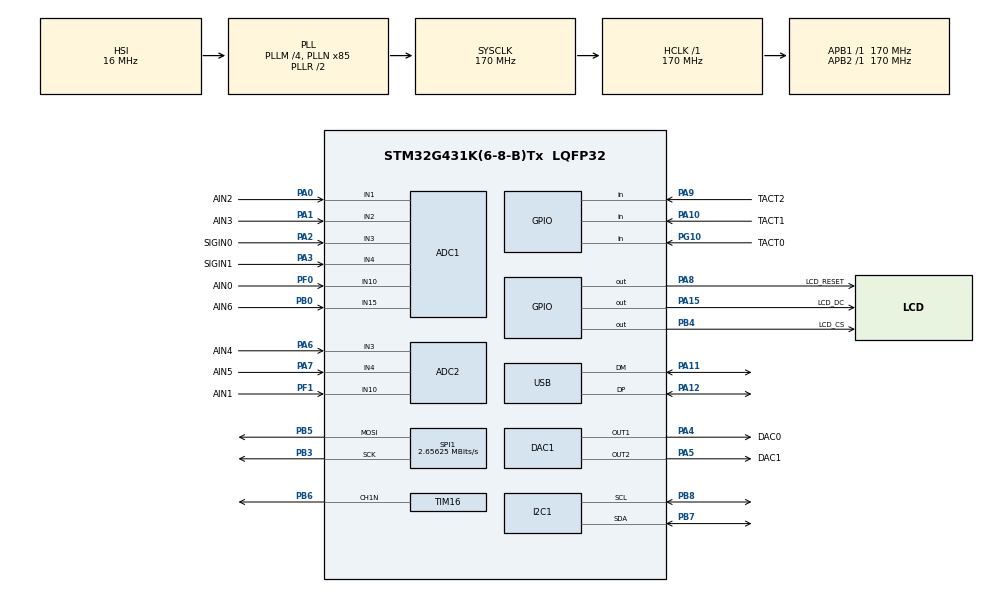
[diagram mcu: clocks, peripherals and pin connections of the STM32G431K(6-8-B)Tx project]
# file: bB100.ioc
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ADC1.Channel-0\#ChannelRegularConversion=ADC_CHANNEL_1
ADC1.Channel-1\#ChannelRegularConversion=ADC_CHANNEL_3
ADC1.Channel-2\#ChannelRegularConversion=ADC_CHANNEL_10
ADC1.Channel-3\#ChannelRegularConversion=ADC_CHANNEL_15
ADC1.EOCSelection=ADC_EOC_SEQ_CONV
ADC1.ExternalTrigConv=ADC_EXTERNALTRIG_T6_TRGO
ADC1.NbrOfConversion=4
ADC1.NbrOfConversionFlag=1
ADC1.OffsetNumber-0\#ChannelRegularConversion=ADC_OFFSET_NONE
ADC1.OffsetNumber-1\#ChannelRegularConversion=ADC_OFFSET_NONE
ADC1.OffsetNumber-2\#ChannelRegularConversion=ADC_OFFSET_NONE
ADC1.OffsetNumber-3\#ChannelRegularConversion=ADC_OFFSET_NONE
ADC1.Rank-0\#ChannelRegularConversion=1
ADC1.Rank-1\#ChannelRegularConversion=2
ADC1.Rank-2\#ChannelRegularConversion=3
ADC1.Rank-3\#ChannelRegularConversion=4
ADC1.SamplingTime-0\#ChannelRegularConversion=ADC_SAMPLETIME_2CYCLES_5
ADC1.SamplingTime-1\#ChannelRegularConversion=ADC_SAMPLETIME_2CYCLES_5
ADC1.SamplingTime-2\#ChannelRegularConversion=ADC_SAMPLETIME_2CYCLES_5
ADC1.SamplingTime-3\#ChannelRegularConversion=ADC_SAMPLETIME_2CYCLES_5
ADC1.SingleDiff-0\#ChannelRegularConversion=ADC_DIFFERENTIAL_ENDED
ADC1.SingleDiff-1\#ChannelRegularConversion=ADC_DIFFERENTIAL_ENDED
ADC1.master=1
ADC2.Channel-0\#ChannelRegularConversion=ADC_CHANNEL_3
ADC2.Channel-1\#ChannelRegularConversion=ADC_CHANNEL_4
ADC2.Channel-2\#ChannelRegularConversion=ADC_CHANNEL_10
ADC2.ExternalTrigConv=ADC_EXTERNALTRIG_T7_TRGO
ADC2.NbrOfConversion=3
ADC2.NbrOfConversionFlag=1
ADC2.OffsetNumber-0\#ChannelRegularConversion=ADC_OFFSET_NONE
ADC2.OffsetNumber-1\#ChannelRegularConversion=ADC_OFFSET_NONE
ADC2.OffsetNumber-2\#ChannelRegularConversion=ADC_OFFSET_NONE
ADC2.Rank-0\#ChannelRegularConversion=1
ADC2.Rank-1\#ChannelRegularConversion=2
ADC2.Rank-2\#ChannelRegularConversion=3
ADC2.SamplingTime-0\#ChannelRegularConversion=ADC_SAMPLETIME_2CYCLES_5
ADC2.SamplingTime-1\#ChannelRegularConversion=ADC_SAMPLETIME_2CYCLES_5
ADC2.SamplingTime-2\#ChannelRegularConversion=ADC_SAMPLETIME_2CYCLES_5
DAC1.DAC_Channel-DAC_OUT2_ExtAndInt=DAC_CHANNEL_2
DAC1.DAC_DMADoubleDataMode-DAC_OUT1_ExtAndInt=DISABLE
DAC1.DAC_SampleAndHold-DAC_OUT1_ExtAndInt=DAC_SAMPLEANDHOLD_DISABLE
DAC1.DAC_Trigger_OUT1-DAC_OUT1_ExtAndInt=DAC_TRIGGER_T6_TRGO
DAC1.DAC_Trigger_OUT2-DAC_OUT2_ExtAndInt=DAC_TRIGGER_T7_TRGO
Dma.ADC1.2.Direction=DMA_PERIPH_TO_MEMORY
Dma.ADC1.2.EventEnable=DISABLE
Dma.ADC1.2.Instance=DMA1_Channel3
Dma.ADC1.2.MemDataAlignment=DMA_MDATAALIGN_HALFWORD
Dma.ADC1.2.MemInc=DMA_MINC_ENABLE
Dma.ADC1.2.Mode=DMA_CIRCULAR
Dma.ADC1.2.PeriphDataAlignment=DMA_PDATAALIGN_HALFWORD
Dma.ADC1.2.PeriphInc=DMA_PINC_DISABLE
Dma.ADC1.2.Polarity=HAL_DMAMUX_REQ_GEN_RISING
Dma.ADC1.2.Priority=DMA_PRIORITY_LOW
Dma.ADC1.2.RequestNumber=1
Dma.ADC1.2.SignalID=NONE
Dma.ADC1.2.SyncEnable=DISABLE
Dma.ADC1.2.SyncPolarity=HAL_DMAMUX_SYNC_NO_EVENT
Dma.ADC1.2.SyncRequestNumber=1
Dma.ADC1.2.SyncSignalID=NONE
Dma.ADC2.3.Direction=DMA_PERIPH_TO_MEMORY
Dma.ADC2.3.EventEnable=DISABLE
Dma.ADC2.3.Instance=DMA1_Channel4
Dma.ADC2.3.MemDataAlignment=DMA_MDATAALIGN_HALFWORD
Dma.ADC2.3.MemInc=DMA_MINC_ENABLE
Dma.ADC2.3.Mode=DMA_CIRCULAR
Dma.ADC2.3.PeriphDataAlignment=DMA_PDATAALIGN_HALFWORD
Dma.ADC2.3.PeriphInc=DMA_PINC_DISABLE
Dma.ADC2.3.Polarity=HAL_DMAMUX_REQ_GEN_RISING
Dma.ADC2.3.Priority=DMA_PRIORITY_LOW
Dma.ADC2.3.RequestNumber=1
Dma.ADC2.3.SignalID=NONE
Dma.ADC2.3.SyncEnable=DISABLE
Dma.ADC2.3.SyncPolarity=HAL_DMAMUX_SYNC_NO_EVENT
Dma.ADC2.3.SyncRequestNumber=1
Dma.ADC2.3.SyncSignalID=NONE
Dma.DAC1_CH1.0.Direction=DMA_MEMORY_TO_PERIPH
Dma.DAC1_CH1.0.EventEnable=DISABLE
Dma.DAC1_CH1.0.Instance=DMA1_Channel1
Dma.DAC1_CH1.0.MemDataAlignment=DMA_MDATAALIGN_HALFWORD
Dma.DAC1_CH1.0.MemInc=DMA_MINC_ENABLE
Dma.DAC1_CH1.0.Mode=DMA_CIRCULAR
Dma.DAC1_CH1.0.PeriphDataAlignment=DMA_PDATAALIGN_HALFWORD
Dma.DAC1_CH1.0.PeriphInc=DMA_PINC_DISABLE
Dma.DAC1_CH1.0.Polarity=HAL_DMAMUX_REQ_GEN_RISING
Dma.DAC1_CH1.0.Priority=DMA_PRIORITY_LOW
Dma.DAC1_CH1.0.RequestNumber=1
Dma.DAC1_CH1.0.SignalID=NONE
Dma.DAC1_CH1.0.SyncEnable=DISABLE
Dma.DAC1_CH1.0.SyncPolarity=HAL_DMAMUX_SYNC_NO_EVENT
Dma.DAC1_CH1.0.SyncRequestNumber=1
Dma.DAC1_CH1.0.SyncSignalID=NONE
Dma.DAC1_CH2.1.Direction=DMA_MEMORY_TO_PERIPH
Dma.DAC1_CH2.1.EventEnable=DISABLE
Dma.DAC1_CH2.1.Instance=DMA1_Channel2
Dma.DAC1_CH2.1.MemDataAlignment=DMA_MDATAALIGN_HALFWORD
Dma.DAC1_CH2.1.MemInc=DMA_MINC_ENABLE
Dma.DAC1_CH2.1.Mode=DMA_CIRCULAR
Dma.DAC1_CH2.1.PeriphDataAlignment=DMA_PDATAALIGN_HALFWORD
Dma.DAC1_CH2.1.PeriphInc=DMA_PINC_DISABLE
Dma.DAC1_CH2.1.Polarity=HAL_DMAMUX_REQ_GEN_RISING
Dma.DAC1_CH2.1.Priority=DMA_PRIORITY_LOW
Dma.DAC1_CH2.1.RequestNumber=1
Dma.DAC1_CH2.1.SignalID=NONE
Dma.DAC1_CH2.1.SyncEnable=DISABLE
Dma.DAC1_CH2.1.SyncPolarity=HAL_DMAMUX_SYNC_NO_EVENT
Dma.DAC1_CH2.1.SyncRequestNumber=1
Dma.DAC1_CH2.1.SyncSignalID=NONE
Dma.Request0=DAC1_CH1
Dma.Request1=DAC1_CH2
Dma.Request2=ADC1
Dma.Request3=ADC2
I2C1.Timing=0x30A0A7FB
Mcu.Family=STM32G4
Mcu.Name=STM32G431K(6-8-B)Tx
Mcu.Package=LQFP32
NVIC.DMA1_Channel1_IRQn=true\:0\:0\:false\:false\:true\:false\:true
NVIC.DMA1_Channel2_IRQn=true\:0\:0\:false\:false\:true\:false\:true
NVIC.DMA1_Channel3_IRQn=true\:0\:0\:false\:false\:true\:false\:true
NVIC.DMA1_Channel4_IRQn=true\:0\:0\:false\:false\:true\:false\:true
NVIC.PriorityGroup=NVIC_PRIORITYGROUP_4
NVIC.USB_LP_IRQn=true\:0\:0\:false\:false\:true\:false\:true
PA0.GPIO_Label=AIN2
PA0.Mode=IN1-Differential
PA0.Signal=ADC1_IN1
PA1.GPIO_Label=AIN3
PA1.Mode=IN1-Differential
PA1.Signal=ADC1_IN2
PA10.GPIO_Label=TACT1
PA10.GPIO_PuPd=GPIO_PULLUP
PA10.Signal=GPIO_Input
PA11.Mode=Device
PA11.Signal=USB_DM
PA12.Mode=Device
PA12.Signal=USB_DP
PA13.Mode=Serial_Wire
PA13.Signal=SYS_JTMS-SWDIO
PA14.Mode=Serial_Wire
PA14.Signal=SYS_JTCK-SWCLK
PA15.GPIO_Label=LCD_DC
PA15.Signal=GPIO_Output
PA2.GPIO_Label=SIGIN0
PA2.Mode=IN3-Differential
PA2.Signal=ADC1_IN3
PA3.GPIO_Label=SIGIN1
PA3.Mode=IN3-Differential
PA3.Signal=ADC1_IN4
PA4.GPIO_Label=DAC0
PA4.Signal=COMP_DAC11_group
PA5.GPIO_Label=DAC1
PA5.Signal=COMP_DAC12_group
PA6.GPIO_Label=AIN4
PA6.Mode=IN3-Single-Ended
PA6.Signal=ADC2_IN3
PA7.GPIO_Label=AIN5
PA7.Mode=IN4-Single-Ended
PA7.Signal=ADC2_IN4
PA8.GPIO_Label=LCD_RESET
PA8.Signal=GPIO_Output
PA9.GPIO_Label=TACT2
PA9.GPIO_PuPd=GPIO_PULLUP
PA9.Signal=GPIO_Input
PB0.GPIO_Label=AIN6
PB0.Mode=IN15-Single-Ended
PB0.Signal=ADC1_IN15
PB3.Mode=TX_Only_Simplex_Unidirect_Master
PB3.Signal=SPI1_SCK
PB4.GPIO_Label=LCD_CS
PB4.Signal=GPIO_Output
PB5.Mode=TX_Only_Simplex_Unidirect_Master
PB5.Signal=SPI1_MOSI
PB6.Mode=PWM Generation1 CH1N
PB6.Signal=TIM16_CH1N
PB7.Mode=I2C
PB7.Signal=I2C1_SDA
PB8-BOOT0.Mode=I2C
PB8-BOOT0.Signal=I2C1_SCL
PF0-OSC_IN.GPIO_Label=AIN0
PF0-OSC_IN.Mode=IN10-Single-Ended
PF0-OSC_IN.Signal=ADC1_IN10
PF1-OSC_OUT.GPIO_Label=AIN1
PF1-OSC_OUT.Mode=IN10-Single-Ended
PF1-OSC_OUT.Signal=ADC2_IN10
PG10-NRST.GPIO_Label=TACT0
PG10-NRST.GPIO_PuPd=GPIO_PULLUP
PG10-NRST.Signal=GPIO_Input
ProjectManager.HeapSize=0x200
ProjectManager.StackSize=0x400
ProjectManager.TargetToolchain=STM32CubeIDE
RCC.ADC12Freq_Value=170000000
RCC.AHBFreq_Value=170000000
RCC.APB1Freq_Value=170000000
RCC.APB1TimFreq_Value=170000000
RCC.APB2Freq_Value=170000000
RCC.APB2TimFreq_Value=170000000
RCC.CK48CLockSelection=RCC_USBCLKSOURCE_HSI48
RCC.CortexFreq_Value=170000000
RCC.EXTERNAL_CLOCK_VALUE=12288000
RCC.HCLKFreq_Value=170000000
RCC.HSE_VALUE=8000000
RCC.HSI48_VALUE=48000000
RCC.HSI_VALUE=16000000
RCC.LSE_VALUE=32768
RCC.PLLM=RCC_PLLM_DIV4
RCC.PLLN=85
RCC.SYSCLKFreq_VALUE=170000000
RCC.SYSCLKSource=RCC_SYSCLKSOURCE_PLLCLK
RCC.USBFreq_Value=48000000
RCC.VCOOutputFreq_Value=340000000
SH.COMP_DAC11_group.0=DAC1_OUT1,DAC_OUT1_ExtAndInt
SH.COMP_DAC12_group.0=DAC1_OUT2,DAC_OUT2_ExtAndInt
SPI1.BaudRatePrescaler=SPI_BAUDRATEPRESCALER_64
SPI1.CalculateBaudRate=2.65625 MBits/s
SPI1.DataSize=SPI_DATASIZE_8BIT
SPI1.Direction=SPI_DIRECTION_2LINES
SPI1.Mode=SPI_MODE_MASTER
SPI1.VirtualType=VM_MASTER
TIM16.Channel=TIM_CHANNEL_1
TIM16.PeriodNoDither=20000
TIM16.Prescaler=170
TIM16.PulseNoDither_1=10000
TIM6.PeriodNoDither=7
TIM6.Prescaler=241
TIM6.TIM_MasterOutputTrigger=TIM_TRGO_UPDATE
TIM7.PeriodNoDither=7
TIM7.Prescaler=241
TIM7.TIM_MasterOutputTrigger=TIM_TRGO_UPDATE
USB_DEVICE.CLASS_NAME_FS=CDC
USB_DEVICE.VirtualMode=Cdc
USB_DEVICE.VirtualModeFS=Cdc_FS
VP_SYS_VS_DBSignals.Mode=DisableDeadBatterySignals
VP_TIM16_VS_ClockSourceINT.Mode=Enable_Timer
VP_TIM1_VS_ClockSourceINT.Mode=Internal
VP_TIM6_VS_ClockSourceINT.Mode=Enable_Timer
VP_TIM7_VS_ClockSourceINT.Mode=Enable_Timer
VP_USB_DEVICE_VS_USB_DEVICE_CDC_FS.Mode=CDC_FS
board=custom

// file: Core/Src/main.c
/* USER CODE BEGIN Header */
/**
  ******************************************************************************
  * @file           : main.c
  * @brief          : Main program body
  ******************************************************************************
  * @attention
  *
  * <h2><center>&copy; Copyright (c) 2021 STMicroelectronics.
  * All rights reserved.</center></h2>
  *
  * This software component is licensed by ST under BSD 3-Clause license,
  * the "License"; You may not use this file except in compliance with the
  * License. You may obtain a copy of the License at:
  *                        opensource.org/licenses/BSD-3-Clause
  *
  ******************************************************************************
  */
/* USER CODE END Header */
#include "main.h"
#include "usb_device.h"

ADC_HandleTypeDef hadc1;
ADC_HandleTypeDef hadc2;
DMA_HandleTypeDef hdma_adc1;
DMA_HandleTypeDef hdma_adc2;

DAC_HandleTypeDef hdac1;
DMA_HandleTypeDef hdma_dac1_ch1;
DMA_HandleTypeDef hdma_dac1_ch2;

I2C_HandleTypeDef hi2c1;

SPI_HandleTypeDef hspi1;

TIM_HandleTypeDef htim1;
TIM_HandleTypeDef htim6;
TIM_HandleTypeDef htim7;
TIM_HandleTypeDef htim16;

void SystemClock_Config(void);
static void MX_GPIO_Init(void);
static void MX_DMA_Init(void);
static void MX_I2C1_Init(void);
static void MX_SPI1_Init(void);
static void MX_TIM16_Init(void);
static void MX_ADC1_Init(void);
static void MX_ADC2_Init(void);
static void MX_DAC1_Init(void);
static void MX_TIM1_Init(void);
static void MX_TIM6_Init(void);
static void MX_TIM7_Init(void);

int main(void)
{

  /* MCU Configuration--------------------------------------------------------*/

  /* Reset of all peripherals, Initializes the Flash interface and the Systick. */
  HAL_Init();

  /* Configure the system clock */
  SystemClock_Config();

  /* Initialize all configured peripherals */
  MX_GPIO_Init();
  MX_DMA_Init();
  MX_I2C1_Init();
  MX_SPI1_Init();
  MX_TIM16_Init();
  MX_USB_Device_Init();
  MX_ADC1_Init();
  MX_ADC2_Init();
  MX_DAC1_Init();
  MX_TIM1_Init();
  MX_TIM6_Init();
  MX_TIM7_Init();
  /* USER CODE BEGIN 2 */
  LcdInit();
  /* USER CODE END 2 */

  /* Infinite loop */
  while (1)
  {

  }
}

void SystemClock_Config(void)
{
  RCC_OscInitTypeDef RCC_OscInitStruct = {0};
  RCC_ClkInitTypeDef RCC_ClkInitStruct = {0};
  RCC_PeriphCLKInitTypeDef PeriphClkInit = {0};

  /** Configure the main internal regulator output voltage
  */
  HAL_PWREx_ControlVoltageScaling(PWR_REGULATOR_VOLTAGE_SCALE1_BOOST);
  /** Initializes the RCC Oscillators according to the specified parameters
  * in the RCC_OscInitTypeDef structure.
  */
  RCC_OscInitStruct.OscillatorType = RCC_OSCILLATORTYPE_HSI|RCC_OSCILLATORTYPE_HSI48;
  RCC_OscInitStruct.HSIState = RCC_HSI_ON;
  RCC_OscInitStruct.HSICalibrationValue = RCC_HSICALIBRATION_DEFAULT;
  RCC_OscInitStruct.HSI48State = RCC_HSI48_ON;
  RCC_OscInitStruct.PLL.PLLState = RCC_PLL_ON;
  RCC_OscInitStruct.PLL.PLLSource = RCC_PLLSOURCE_HSI;
  RCC_OscInitStruct.PLL.PLLM = RCC_PLLM_DIV4;
  RCC_OscInitStruct.PLL.PLLN = 85;
  RCC_OscInitStruct.PLL.PLLP = RCC_PLLP_DIV2;
  RCC_OscInitStruct.PLL.PLLQ = RCC_PLLQ_DIV2;
  RCC_OscInitStruct.PLL.PLLR = RCC_PLLR_DIV2;
  if (HAL_RCC_OscConfig(&RCC_OscInitStruct) != HAL_OK)
  {
    Error_Handler();
  }
  /** Initializes the CPU, AHB and APB buses clocks
  */
  RCC_ClkInitStruct.ClockType = RCC_CLOCKTYPE_HCLK|RCC_CLOCKTYPE_SYSCLK
                              |RCC_CLOCKTYPE_PCLK1|RCC_CLOCKTYPE_PCLK2;
  RCC_ClkInitStruct.SYSCLKSource = RCC_SYSCLKSOURCE_PLLCLK;
  RCC_ClkInitStruct.AHBCLKDivider = RCC_SYSCLK_DIV1;
  RCC_ClkInitStruct.APB1CLKDivider = RCC_HCLK_DIV1;
  RCC_ClkInitStruct.APB2CLKDivider = RCC_HCLK_DIV1;

  if (HAL_RCC_ClockConfig(&RCC_ClkInitStruct, FLASH_LATENCY_4) != HAL_OK)
  {
    Error_Handler();
  }
  /** Initializes the peripherals clocks
  */
  PeriphClkInit.PeriphClockSelection = RCC_PERIPHCLK_I2C1|RCC_PERIPHCLK_USB
                              |RCC_PERIPHCLK_ADC12;
  PeriphClkInit.I2c1ClockSelection = RCC_I2C1CLKSOURCE_PCLK1;
  PeriphClkInit.UsbClockSelection = RCC_USBCLKSOURCE_HSI48;
  PeriphClkInit.Adc12ClockSelection = RCC_ADC12CLKSOURCE_SYSCLK;
  if (HAL_RCCEx_PeriphCLKConfig(&PeriphClkInit) != HAL_OK)
  {
    Error_Handler();
  }
}

static void MX_ADC1_Init(void)
{

  ADC_MultiModeTypeDef multimode = {0};
  ADC_ChannelConfTypeDef sConfig = {0};

  /** Common config
  */
  hadc1.Instance = ADC1;
  hadc1.Init.ClockPrescaler = ADC_CLOCK_SYNC_PCLK_DIV4;
  hadc1.Init.Resolution = ADC_RESOLUTION_12B;
  hadc1.Init.DataAlign = ADC_DATAALIGN_RIGHT;
  hadc1.Init.GainCompensation = 0;
  hadc1.Init.ScanConvMode = ADC_SCAN_ENABLE;
  hadc1.Init.EOCSelection = ADC_EOC_SEQ_CONV;
  hadc1.Init.LowPowerAutoWait = DISABLE;
  hadc1.Init.ContinuousConvMode = DISABLE;
  hadc1.Init.NbrOfConversion = 4;
  hadc1.Init.DiscontinuousConvMode = DISABLE;
  hadc1.Init.ExternalTrigConv = ADC_EXTERNALTRIG_T6_TRGO;
  hadc1.Init.ExternalTrigConvEdge = ADC_EXTERNALTRIGCONVEDGE_RISING;
  hadc1.Init.DMAContinuousRequests = DISABLE;
  hadc1.Init.Overrun = ADC_OVR_DATA_PRESERVED;
  hadc1.Init.OversamplingMode = DISABLE;
  if (HAL_ADC_Init(&hadc1) != HAL_OK)
  {
    Error_Handler();
  }
  /** Configure the ADC multi-mode
  */
  multimode.Mode = ADC_MODE_INDEPENDENT;
  if (HAL_ADCEx_MultiModeConfigChannel(&hadc1, &multimode) != HAL_OK)
  {
    Error_Handler();
  }
  /** Configure Regular Channel
  */
  sConfig.Channel = ADC_CHANNEL_1;
  sConfig.Rank = ADC_REGULAR_RANK_1;
  sConfig.SamplingTime = ADC_SAMPLETIME_2CYCLES_5;
  sConfig.SingleDiff = ADC_DIFFERENTIAL_ENDED;
  sConfig.OffsetNumber = ADC_OFFSET_NONE;
  sConfig.Offset = 0;
  if (HAL_ADC_ConfigChannel(&hadc1, &sConfig) != HAL_OK)
  {
    Error_Handler();
  }
  /** Configure Regular Channel
  */
  sConfig.Channel = ADC_CHANNEL_3;
  sConfig.Rank = ADC_REGULAR_RANK_2;
  if (HAL_ADC_ConfigChannel(&hadc1, &sConfig) != HAL_OK)
  {
    Error_Handler();
  }
  /** Configure Regular Channel
  */
  sConfig.Channel = ADC_CHANNEL_10;
  sConfig.Rank = ADC_REGULAR_RANK_3;
  sConfig.SingleDiff = ADC_SINGLE_ENDED;
  if (HAL_ADC_ConfigChannel(&hadc1, &sConfig) != HAL_OK)
  {
    Error_Handler();
  }
  /** Configure Regular Channel
  */
  sConfig.Channel = ADC_CHANNEL_15;
  sConfig.Rank = ADC_REGULAR_RANK_4;
  if (HAL_ADC_ConfigChannel(&hadc1, &sConfig) != HAL_OK)
  {
    Error_Handler();
  }

}

static void MX_ADC2_Init(void)
{

  ADC_ChannelConfTypeDef sConfig = {0};

  /** Common config
  */
  hadc2.Instance = ADC2;
  hadc2.Init.ClockPrescaler = ADC_CLOCK_SYNC_PCLK_DIV4;
  hadc2.Init.Resolution = ADC_RESOLUTION_12B;
  hadc2.Init.DataAlign = ADC_DATAALIGN_RIGHT;
  hadc2.Init.GainCompensation = 0;
  hadc2.Init.ScanConvMode = ADC_SCAN_ENABLE;
  hadc2.Init.EOCSelection = ADC_EOC_SINGLE_CONV;
  hadc2.Init.LowPowerAutoWait = DISABLE;
  hadc2.Init.ContinuousConvMode = DISABLE;
  hadc2.Init.NbrOfConversion = 3;
  hadc2.Init.DiscontinuousConvMode = DISABLE;
  hadc2.Init.ExternalTrigConv = ADC_EXTERNALTRIG_T7_TRGO;
  hadc2.Init.ExternalTrigConvEdge = ADC_EXTERNALTRIGCONVEDGE_RISING;
  hadc2.Init.DMAContinuousRequests = DISABLE;
  hadc2.Init.Overrun = ADC_OVR_DATA_PRESERVED;
  hadc2.Init.OversamplingMode = DISABLE;
  if (HAL_ADC_Init(&hadc2) != HAL_OK)
  {
    Error_Handler();
  }
  /** Configure Regular Channel
  */
  sConfig.Channel = ADC_CHANNEL_3;
  sConfig.Rank = ADC_REGULAR_RANK_1;
  sConfig.SamplingTime = ADC_SAMPLETIME_2CYCLES_5;
  sConfig.SingleDiff = ADC_SINGLE_ENDED;
  sConfig.OffsetNumber = ADC_OFFSET_NONE;
  sConfig.Offset = 0;
  if (HAL_ADC_ConfigChannel(&hadc2, &sConfig) != HAL_OK)
  {
    Error_Handler();
  }
  /** Configure Regular Channel
  */
  sConfig.Channel = ADC_CHANNEL_4;
  sConfig.Rank = ADC_REGULAR_RANK_2;
  if (HAL_ADC_ConfigChannel(&hadc2, &sConfig) != HAL_OK)
  {
    Error_Handler();
  }
  /** Configure Regular Channel
  */
  sConfig.Channel = ADC_CHANNEL_10;
  sConfig.Rank = ADC_REGULAR_RANK_3;
  if (HAL_ADC_ConfigChannel(&hadc2, &sConfig) != HAL_OK)
  {
    Error_Handler();
  }

}

static void MX_DAC1_Init(void)
{

  DAC_ChannelConfTypeDef sConfig = {0};

  /** DAC Initialization
  */
  hdac1.Instance = DAC1;
  if (HAL_DAC_Init(&hdac1) != HAL_OK)
  {
    Error_Handler();
  }
  /** DAC channel OUT1 config
  */
  sConfig.DAC_HighFrequency = DAC_HIGH_FREQUENCY_INTERFACE_MODE_AUTOMATIC;
  sConfig.DAC_DMADoubleDataMode = DISABLE;
  sConfig.DAC_SignedFormat = DISABLE;
  sConfig.DAC_SampleAndHold = DAC_SAMPLEANDHOLD_DISABLE;
  sConfig.DAC_Trigger = DAC_TRIGGER_T6_TRGO;
  sConfig.DAC_Trigger2 = DAC_TRIGGER_NONE;
  sConfig.DAC_OutputBuffer = DAC_OUTPUTBUFFER_ENABLE;
  sConfig.DAC_ConnectOnChipPeripheral = DAC_CHIPCONNECT_BOTH;
  sConfig.DAC_UserTrimming = DAC_TRIMMING_FACTORY;
  if (HAL_DAC_ConfigChannel(&hdac1, &sConfig, DAC_CHANNEL_1) != HAL_OK)
  {
    Error_Handler();
  }
  /** DAC channel OUT2 config
  */
  sConfig.DAC_Trigger = DAC_TRIGGER_T7_TRGO;
  sConfig.DAC_ConnectOnChipPeripheral = DAC_CHIPCONNECT_BOTH;
  if (HAL_DAC_ConfigChannel(&hdac1, &sConfig, DAC_CHANNEL_2) != HAL_OK)
  {
    Error_Handler();
  }

}

static void MX_I2C1_Init(void)
{

  hi2c1.Instance = I2C1;
  hi2c1.Init.Timing = 0x30A0A7FB;
  hi2c1.Init.OwnAddress1 = 0;
  hi2c1.Init.AddressingMode = I2C_ADDRESSINGMODE_7BIT;
  hi2c1.Init.DualAddressMode = I2C_DUALADDRESS_DISABLE;
  hi2c1.Init.OwnAddress2 = 0;
  hi2c1.Init.OwnAddress2Masks = I2C_OA2_NOMASK;
  hi2c1.Init.GeneralCallMode = I2C_GENERALCALL_DISABLE;
  hi2c1.Init.NoStretchMode = I2C_NOSTRETCH_DISABLE;
  if (HAL_I2C_Init(&hi2c1) != HAL_OK)
  {
    Error_Handler();
  }
  /** Configure Analogue filter
  */
  if (HAL_I2CEx_ConfigAnalogFilter(&hi2c1, I2C_ANALOGFILTER_ENABLE) != HAL_OK)
  {
    Error_Handler();
  }
  /** Configure Digital filter
  */
  if (HAL_I2CEx_ConfigDigitalFilter(&hi2c1, 0) != HAL_OK)
  {
    Error_Handler();
  }

}

static void MX_SPI1_Init(void)
{

  /* SPI1 parameter configuration*/
  hspi1.Instance = SPI1;
  hspi1.Init.Mode = SPI_MODE_MASTER;
  hspi1.Init.Direction = SPI_DIRECTION_2LINES;
  hspi1.Init.DataSize = SPI_DATASIZE_8BIT;
  hspi1.Init.CLKPolarity = SPI_POLARITY_LOW;
  hspi1.Init.CLKPhase = SPI_PHASE_1EDGE;
  hspi1.Init.NSS = SPI_NSS_SOFT;
  hspi1.Init.BaudRatePrescaler = SPI_BAUDRATEPRESCALER_64;
  hspi1.Init.FirstBit = SPI_FIRSTBIT_MSB;
  hspi1.Init.TIMode = SPI_TIMODE_DISABLE;
  hspi1.Init.CRCCalculation = SPI_CRCCALCULATION_DISABLE;
  hspi1.Init.CRCPolynomial = 7;
  hspi1.Init.CRCLength = SPI_CRC_LENGTH_DATASIZE;
  hspi1.Init.NSSPMode = SPI_NSS_PULSE_ENABLE;
  if (HAL_SPI_Init(&hspi1) != HAL_OK)
  {
    Error_Handler();
  }

}

static void MX_TIM1_Init(void)
{

  TIM_ClockConfigTypeDef sClockSourceConfig = {0};
  TIM_MasterConfigTypeDef sMasterConfig = {0};
  TIM_BreakDeadTimeConfigTypeDef sBreakDeadTimeConfig = {0};

  htim1.Instance = TIM1;
  htim1.Init.Prescaler = 0;
  htim1.Init.CounterMode = TIM_COUNTERMODE_UP;
  htim1.Init.Period = 65535;
  htim1.Init.ClockDivision = TIM_CLOCKDIVISION_DIV1;
  htim1.Init.RepetitionCounter = 0;
  htim1.Init.AutoReloadPreload = TIM_AUTORELOAD_PRELOAD_DISABLE;
  if (HAL_TIM_Base_Init(&htim1) != HAL_OK)
  {
    Error_Handler();
  }
  sClockSourceConfig.ClockSource = TIM_CLOCKSOURCE_INTERNAL;
  if (HAL_TIM_ConfigClockSource(&htim1, &sClockSourceConfig) != HAL_OK)
  {
    Error_Handler();
  }
  sMasterConfig.MasterOutputTrigger = TIM_TRGO_RESET;
  sMasterConfig.MasterOutputTrigger2 = TIM_TRGO2_RESET;
  sMasterConfig.MasterSlaveMode = TIM_MASTERSLAVEMODE_DISABLE;
  if (HAL_TIMEx_MasterConfigSynchronization(&htim1, &sMasterConfig) != HAL_OK)
  {
    Error_Handler();
  }
  sBreakDeadTimeConfig.BreakAFMode = TIM_BREAK_AFMODE_INPUT;
  sBreakDeadTimeConfig.Break2AFMode = TIM_BREAK_AFMODE_INPUT;
  if (HAL_TIMEx_ConfigBreakDeadTime(&htim1, &sBreakDeadTimeConfig) != HAL_OK)
  {
    Error_Handler();
  }

}

static void MX_TIM6_Init(void)
{

  TIM_MasterConfigTypeDef sMasterConfig = {0};

  htim6.Instance = TIM6;
  htim6.Init.Prescaler = 241;
  htim6.Init.CounterMode = TIM_COUNTERMODE_UP;
  htim6.Init.Period = 7;
  htim6.Init.AutoReloadPreload = TIM_AUTORELOAD_PRELOAD_DISABLE;
  if (HAL_TIM_Base_Init(&htim6) != HAL_OK)
  {
    Error_Handler();
  }
  sMasterConfig.MasterOutputTrigger = TIM_TRGO_UPDATE;
  sMasterConfig.MasterSlaveMode = TIM_MASTERSLAVEMODE_DISABLE;
  if (HAL_TIMEx_MasterConfigSynchronization(&htim6, &sMasterConfig) != HAL_OK)
  {
    Error_Handler();
  }

}

static void MX_TIM7_Init(void)
{

  TIM_MasterConfigTypeDef sMasterConfig = {0};

  htim7.Instance = TIM7;
  htim7.Init.Prescaler = 241;
  htim7.Init.CounterMode = TIM_COUNTERMODE_UP;
  htim7.Init.Period = 7;
  htim7.Init.AutoReloadPreload = TIM_AUTORELOAD_PRELOAD_DISABLE;
  if (HAL_TIM_Base_Init(&htim7) != HAL_OK)
  {
    Error_Handler();
  }
  sMasterConfig.MasterOutputTrigger = TIM_TRGO_UPDATE;
  sMasterConfig.MasterSlaveMode = TIM_MASTERSLAVEMODE_DISABLE;
  if (HAL_TIMEx_MasterConfigSynchronization(&htim7, &sMasterConfig) != HAL_OK)
  {
    Error_Handler();
  }

}

static void MX_TIM16_Init(void)
{

  TIM_OC_InitTypeDef sConfigOC = {0};
  TIM_BreakDeadTimeConfigTypeDef sBreakDeadTimeConfig = {0};

  htim16.Instance = TIM16;
  htim16.Init.Prescaler = 170;
  htim16.Init.CounterMode = TIM_COUNTERMODE_UP;
  htim16.Init.Period = 20000;
  htim16.Init.ClockDivision = TIM_CLOCKDIVISION_DIV1;
  htim16.Init.RepetitionCounter = 0;
  htim16.Init.AutoReloadPreload = TIM_AUTORELOAD_PRELOAD_DISABLE;
  if (HAL_TIM_Base_Init(&htim16) != HAL_OK)
  {
    Error_Handler();
  }
  if (HAL_TIM_PWM_Init(&htim16) != HAL_OK)
  {
    Error_Handler();
  }
  sConfigOC.OCMode = TIM_OCMODE_PWM1;
  sConfigOC.Pulse = 10000;
  sConfigOC.OCPolarity = TIM_OCPOLARITY_HIGH;
  sConfigOC.OCNPolarity = TIM_OCNPOLARITY_HIGH;
  sConfigOC.OCFastMode = TIM_OCFAST_DISABLE;
  sConfigOC.OCIdleState = TIM_OCIDLESTATE_RESET;
  sConfigOC.OCNIdleState = TIM_OCNIDLESTATE_RESET;
  if (HAL_TIM_PWM_ConfigChannel(&htim16, &sConfigOC, TIM_CHANNEL_1) != HAL_OK)
  {
    Error_Handler();
  }
  sBreakDeadTimeConfig.OffStateRunMode = TIM_OSSR_DISABLE;
  sBreakDeadTimeConfig.OffStateIDLEMode = TIM_OSSI_DISABLE;
  sBreakDeadTimeConfig.LockLevel = TIM_LOCKLEVEL_OFF;
  sBreakDeadTimeConfig.DeadTime = 0;
  sBreakDeadTimeConfig.BreakState = TIM_BREAK_DISABLE;
  sBreakDeadTimeConfig.BreakPolarity = TIM_BREAKPOLARITY_HIGH;
  sBreakDeadTimeConfig.BreakFilter = 0;
  sBreakDeadTimeConfig.AutomaticOutput = TIM_AUTOMATICOUTPUT_DISABLE;
  if (HAL_TIMEx_ConfigBreakDeadTime(&htim16, &sBreakDeadTimeConfig) != HAL_OK)
  {
    Error_Handler();
  }
  HAL_TIM_MspPostInit(&htim16);

}

static void MX_DMA_Init(void)
{

  /* DMA controller clock enable */
  __HAL_RCC_DMAMUX1_CLK_ENABLE();
  __HAL_RCC_DMA1_CLK_ENABLE();

  /* DMA interrupt init */
  /* DMA1_Channel1_IRQn interrupt configuration */
  HAL_NVIC_SetPriority(DMA1_Channel1_IRQn, 0, 0);
  HAL_NVIC_EnableIRQ(DMA1_Channel1_IRQn);
  /* DMA1_Channel2_IRQn interrupt configuration */
  HAL_NVIC_SetPriority(DMA1_Channel2_IRQn, 0, 0);
  HAL_NVIC_EnableIRQ(DMA1_Channel2_IRQn);
  /* DMA1_Channel3_IRQn interrupt configuration */
  HAL_NVIC_SetPriority(DMA1_Channel3_IRQn, 0, 0);
  HAL_NVIC_EnableIRQ(DMA1_Channel3_IRQn);
  /* DMA1_Channel4_IRQn interrupt configuration */
  HAL_NVIC_SetPriority(DMA1_Channel4_IRQn, 0, 0);
  HAL_NVIC_EnableIRQ(DMA1_Channel4_IRQn);

}

static void MX_GPIO_Init(void)
{
  GPIO_InitTypeDef GPIO_InitStruct = {0};

  /* GPIO Ports Clock Enable */
  __HAL_RCC_GPIOF_CLK_ENABLE();
  __HAL_RCC_GPIOG_CLK_ENABLE();
  __HAL_RCC_GPIOA_CLK_ENABLE();
  __HAL_RCC_GPIOB_CLK_ENABLE();

  /*Configure GPIO pin Output Level */
  HAL_GPIO_WritePin(GPIOA, LCD_RESET_Pin|LCD_DC_Pin, GPIO_PIN_RESET);

  /*Configure GPIO pin Output Level */
  HAL_GPIO_WritePin(LCD_CS_GPIO_Port, LCD_CS_Pin, GPIO_PIN_RESET);

  /*Configure GPIO pin : TACT0_Pin */
  GPIO_InitStruct.Pin = TACT0_Pin;
  GPIO_InitStruct.Mode = GPIO_MODE_INPUT;
  GPIO_InitStruct.Pull = GPIO_PULLUP;
  HAL_GPIO_Init(TACT0_GPIO_Port, &GPIO_InitStruct);

  /*Configure GPIO pins : LCD_RESET_Pin LCD_DC_Pin */
  GPIO_InitStruct.Pin = LCD_RESET_Pin|LCD_DC_Pin;
  GPIO_InitStruct.Mode = GPIO_MODE_OUTPUT_PP;
  GPIO_InitStruct.Pull = GPIO_NOPULL;
  GPIO_InitStruct.Speed = GPIO_SPEED_FREQ_LOW;
  HAL_GPIO_Init(GPIOA, &GPIO_InitStruct);

  /*Configure GPIO pins : TACT2_Pin TACT1_Pin */
  GPIO_InitStruct.Pin = TACT2_Pin|TACT1_Pin;
  GPIO_InitStruct.Mode = GPIO_MODE_INPUT;
  GPIO_InitStruct.Pull = GPIO_PULLUP;
  HAL_GPIO_Init(GPIOA, &GPIO_InitStruct);

  /*Configure GPIO pin : LCD_CS_Pin */
  GPIO_InitStruct.Pin = LCD_CS_Pin;
  GPIO_InitStruct.Mode = GPIO_MODE_OUTPUT_PP;
  GPIO_InitStruct.Pull = GPIO_NOPULL;
  GPIO_InitStruct.Speed = GPIO_SPEED_FREQ_LOW;
  HAL_GPIO_Init(LCD_CS_GPIO_Port, &GPIO_InitStruct);

}

void Error_Handler(void)
{
  __disable_irq();
  while (1)
  {
  }
}

/************************ (C) COPYRIGHT STMicroelectronics *****END OF FILE****/
